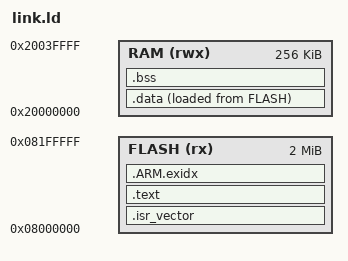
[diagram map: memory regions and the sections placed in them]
/* link.ld — STM32F407-class memory: 1 MB flash, 128 KB SRAM (the simulated part has more; the map shows real usage) */
ENTRY(Reset_Handler)
MEMORY { FLASH (rx) : ORIGIN = 0x08000000, LENGTH = 2048K
         RAM (rwx)  : ORIGIN = 0x20000000, LENGTH = 256K }
_estack = ORIGIN(RAM) + LENGTH(RAM);
SECTIONS {
  .isr_vector : { KEEP(*(.isr_vector)) } > FLASH
  .text : { *(.text*) *(.rodata*) *(.glue_7) *(.glue_7t) KEEP(*(.init)) KEEP(*(.fini)) } > FLASH
  .ARM.exidx : { *(.ARM.exidx*) } > FLASH
  _sidata = LOADADDR(.data);
  .data : { _sdata = .; *(.data*) _edata = .; } > RAM AT > FLASH
  .bss : { _sbss = .; *(.bss*) *(COMMON) _ebss = .; } > RAM
  _end = .; end = .;
}
